# AE822FA0E5597BS0_CM55_HE_View register map
Vendor: Alif Semiconductor; Series: E8; File version: 1.0
CPU: CM55 r1p0, selectable endian, MPU, FPU, double-precision FPU, DSP, VTOR, 8 interrupt priority bits, 1 SAU regions
Registers are 32-bit, read-write, reset 0x0 unless marked. A register's access mark holds for its fields unless they carry their own. Offsets are from the block's base; [hi:lo] are bit positions; lines under a group give offsets from that group; {n}, {i} and the like mark numbered series.

## LPPDM
Base 0x43002000
Same registers: PDM 0x4902D000
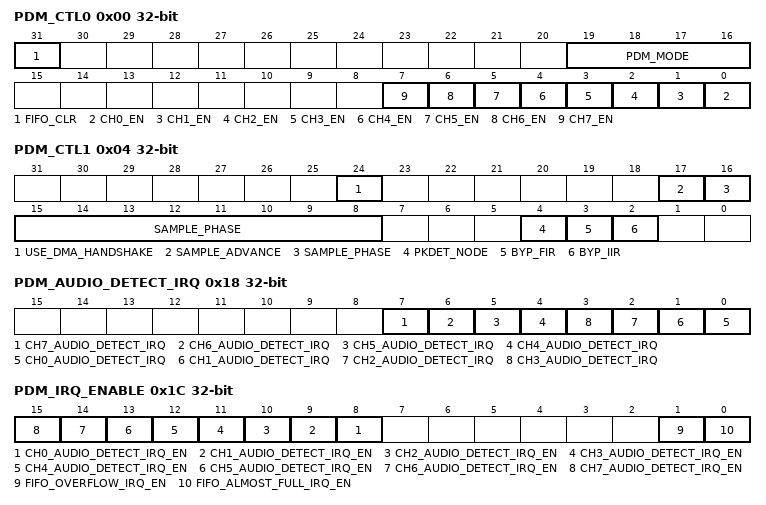
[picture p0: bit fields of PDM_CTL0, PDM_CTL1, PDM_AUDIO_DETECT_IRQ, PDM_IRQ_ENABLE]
0x00 PDM_CTL0 — PDM Audio Control Register 0
  [31] FIFO_CLR — FIFO clear
  [19:16] PDM_MODE — PDM clock frequency selection for all channels. For more details about these modes,PDM Modes.
    0=PDM mode 0; 1=PDM mode 1; 9=PDM mode 9
  [n] CH{n}_EN (n=0..7) — Channel {n} enable.
    0=Disable and soft-clear; 1=Enable
0x04 PDM_CTL1 — PDM Audio Control Register 1
  [24] USE_DMA_HANDSHAKE — Use DMA handshaking signals for flow control.
  [17] SAMPLE_ADVANCE — Sampling of PDM data by SAMPLE_PHASE number of PDM_CLK periods around PDM_Ci edges. Adjust to compensate for routing delay skew between PDM_Ci and PDM_Di and to meet sampling time requirement of the microphone.
    0=Retard sampling; 1=Advance sampling
  [16:8] SAMPLE_PHASE — Sampling phase of PDM data in units of PDM_CLK period. Adjust to compensate for routing delay skew between PDM_Ci and PDM_Di and to meet sampling time requirement of the microphone.
  [4] PKDET_NODE — Peak detection node.
    0=Before gain stage; 1=After gain stage
  [3] BYP_FIR — Bypass FIR filter.
  [2] BYP_IIR — Bypass DC blocking IIR filter.
0x08 PDM_FIFO_WATERMARK_H reset 0x4 — FIFO Watermark Register
  [3:0] WATERMARK_H — Threshold to trigger FIFO almost full warning interrupt
0x0C PDM_FIFO_STAT ro — FIFO Status Register
  [3:0] CNT — Count of sets of audio data entry in FIFO for each channel available to be read. A set consists of one PDM sample per channel.
0x10 PDM_ERROR_IRQ ro — FIFO Error Interrupt Status Register
  [0] FIFO_OVERFLOW_IRQ read-clears — Asserts if audio stream causes FIFO overflow
0x14 PDM_WARN_IRQ ro — FIFO Warning Interrupt Status Register
  [0] FIFO_ALMOST_FULL_IRQ read-clears — Alerts the Host that FIFO fill level has reached or exceeded the PDM_FIFO_WATERMARK_H threshold and audio data should be read to avoid FIFO overflow error.
0x18 PDM_AUDIO_DETECT_IRQ ro — Audio Detection Interrupt Status Register
  [7] CH7_AUDIO_DETECT_IRQ read-clears — Asserts if the peak absolute value of audio signal in channel 7 exceeds the peak detector high threshold for the channel
  [6] CH6_AUDIO_DETECT_IRQ read-clears — Asserts if the peak absolute value of audio signal in channel 6 exceeds the peak detector high threshold for the channel
  [5] CH5_AUDIO_DETECT_IRQ read-clears — Asserts if the peak absolute value of audio signal in channel 5 exceeds the peak detector high threshold for the channel
  [4] CH4_AUDIO_DETECT_IRQ read-clears — Asserts if the peak absolute value of audio signal in channel 5 exceeds the peak detector high threshold for the channel
  [n] CH{n}_AUDIO_DETECT_IRQ read-clears (n=0..3) — Asserts if the peak absolute value of audio signal in channel {n} exceeds the peak detector high threshold for the channel
0x1C PDM_IRQ_ENABLE — Interrupt Enable Register
  [n+8] CH{n}_AUDIO_DETECT_IRQ_EN (n=0..7) — Channel {n} audio peak detection interrupt enable
  [1] FIFO_OVERFLOW_IRQ_EN — FIFO overflow error interrupt enable
  [0] FIFO_ALMOST_FULL_IRQ_EN — FIFO almost full warning interrupt enable
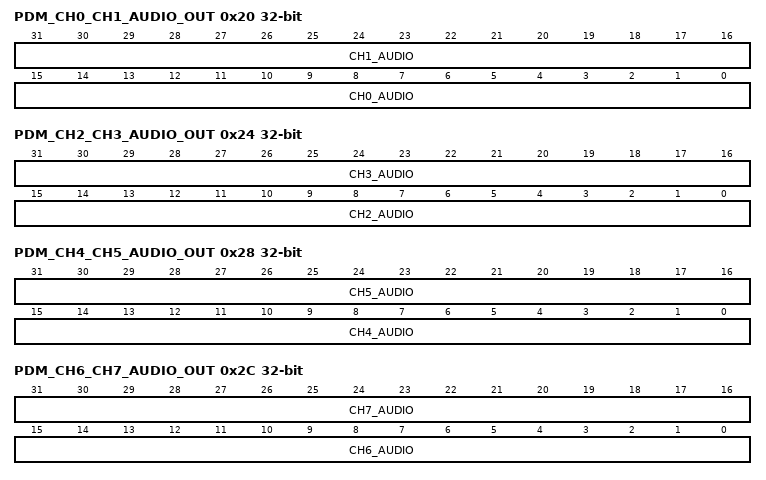
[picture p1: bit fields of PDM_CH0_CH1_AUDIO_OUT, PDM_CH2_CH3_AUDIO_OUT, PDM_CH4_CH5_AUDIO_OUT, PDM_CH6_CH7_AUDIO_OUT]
0x20 PDM_CH0_CH1_AUDIO_OUT — Channels 0 and 1 Audio Output Register
  [31:16] CH1_AUDIO — Channel 1 audio output
  [15:0] CH0_AUDIO — Channel 0 audio output
0x24 PDM_CH2_CH3_AUDIO_OUT — Channels 2 and 3 Audio Output Register
  [31:16] CH3_AUDIO — Channel 3 audio output
  [15:0] CH2_AUDIO — Channel 2 audio output
0x28 PDM_CH4_CH5_AUDIO_OUT — Channels 4 and 5 Audio Output Register
  [31:16] CH5_AUDIO — Channel 5 audio output
  [15:0] CH4_AUDIO — Channel 4 audio output
0x2C PDM_CH6_CH7_AUDIO_OUT — Channels 6 and 7 Audio Output Register
  [31:16] CH7_AUDIO — Channel 7 audio output
  [15:0] CH6_AUDIO — Channel 6 audio output
{0x40+0x100*i} PDM_CHANNEL_CFG[{i}] (i=0..7) group
  {0x0+4j} PDM_CH_FIR_COEF_{j} (j=0..17) — Channel (n) FIR Filter Coefficient {j} Register
    [10:0] FIR_COEF_{j} — FIR coefficient {j}. 11 bits signed 2's complement with 10 bits of fraction. Quantize to Matlab 11.10 format. Decimal range is (-1, 1-2^-10).
  0x80 PDM_CH_IIR_COEF_SEL reset 0x9 — Channel (n) IIR Filter Coefficient Selection Register
    [4:0] COEFSEL — IIR filter coefficient selector for DC blocker filter characterized with the following transfer function: H(z) = (1 - z^-1) / (1 - a x z^-1), where a = 1 - (2^-COEFSEL).
  0x84 PDM_CH_PHASE — Channel (n) Phase Control Register
    [5:0] PHASE — Channel phase delay in units of PDM_Ci cycle counts
  0x88 PDM_CH_GAIN reset 0x10 — Channel (n) Gain Control Register
    [11:0] GAIN — Gain in unsigned 8.4 format (Matlab 12.4 format)
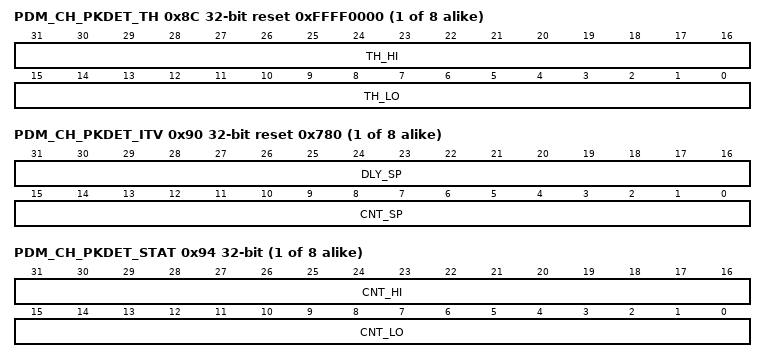
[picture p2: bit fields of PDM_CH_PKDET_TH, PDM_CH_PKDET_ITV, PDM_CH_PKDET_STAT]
  0x8C PDM_CH_PKDET_TH reset 0xFFFF0000 — Channel (n) Peak Detector Threshold Register
    [31:16] TH_HI — High threshold for peak detection
    [15:0] TH_LO — Low threshold for peak detection
  0x90 PDM_CH_PKDET_ITV reset 0x780 — Channel (n) Peak Detector Interval Register
    [31:16] DLY_SP — Number of samples to skip before peak detection starts
    [15:0] CNT_SP — Number of samples to use for peak detection
  0x94 PDM_CH_PKDET_STAT ro — Channel (n) Peak Detector Status Register
    [31:16] CNT_HI — High peak count. Number of occurrences of the absolute value of audio signal exceeding PDM_CHn_PKDET_TH[TH_HI] threshold in the most recent peak detection interval specified by PDM_CHn_PKDET_ITV register.
    [15:0] CNT_LO — Low peak count. Number of occurrences of the absolute value of audio signal going below PDM_CHn_PKDET_TH[TH_LO] threshold in the most recent peak detection interval specified by PDM_CHn_PKDET_ITV register.
